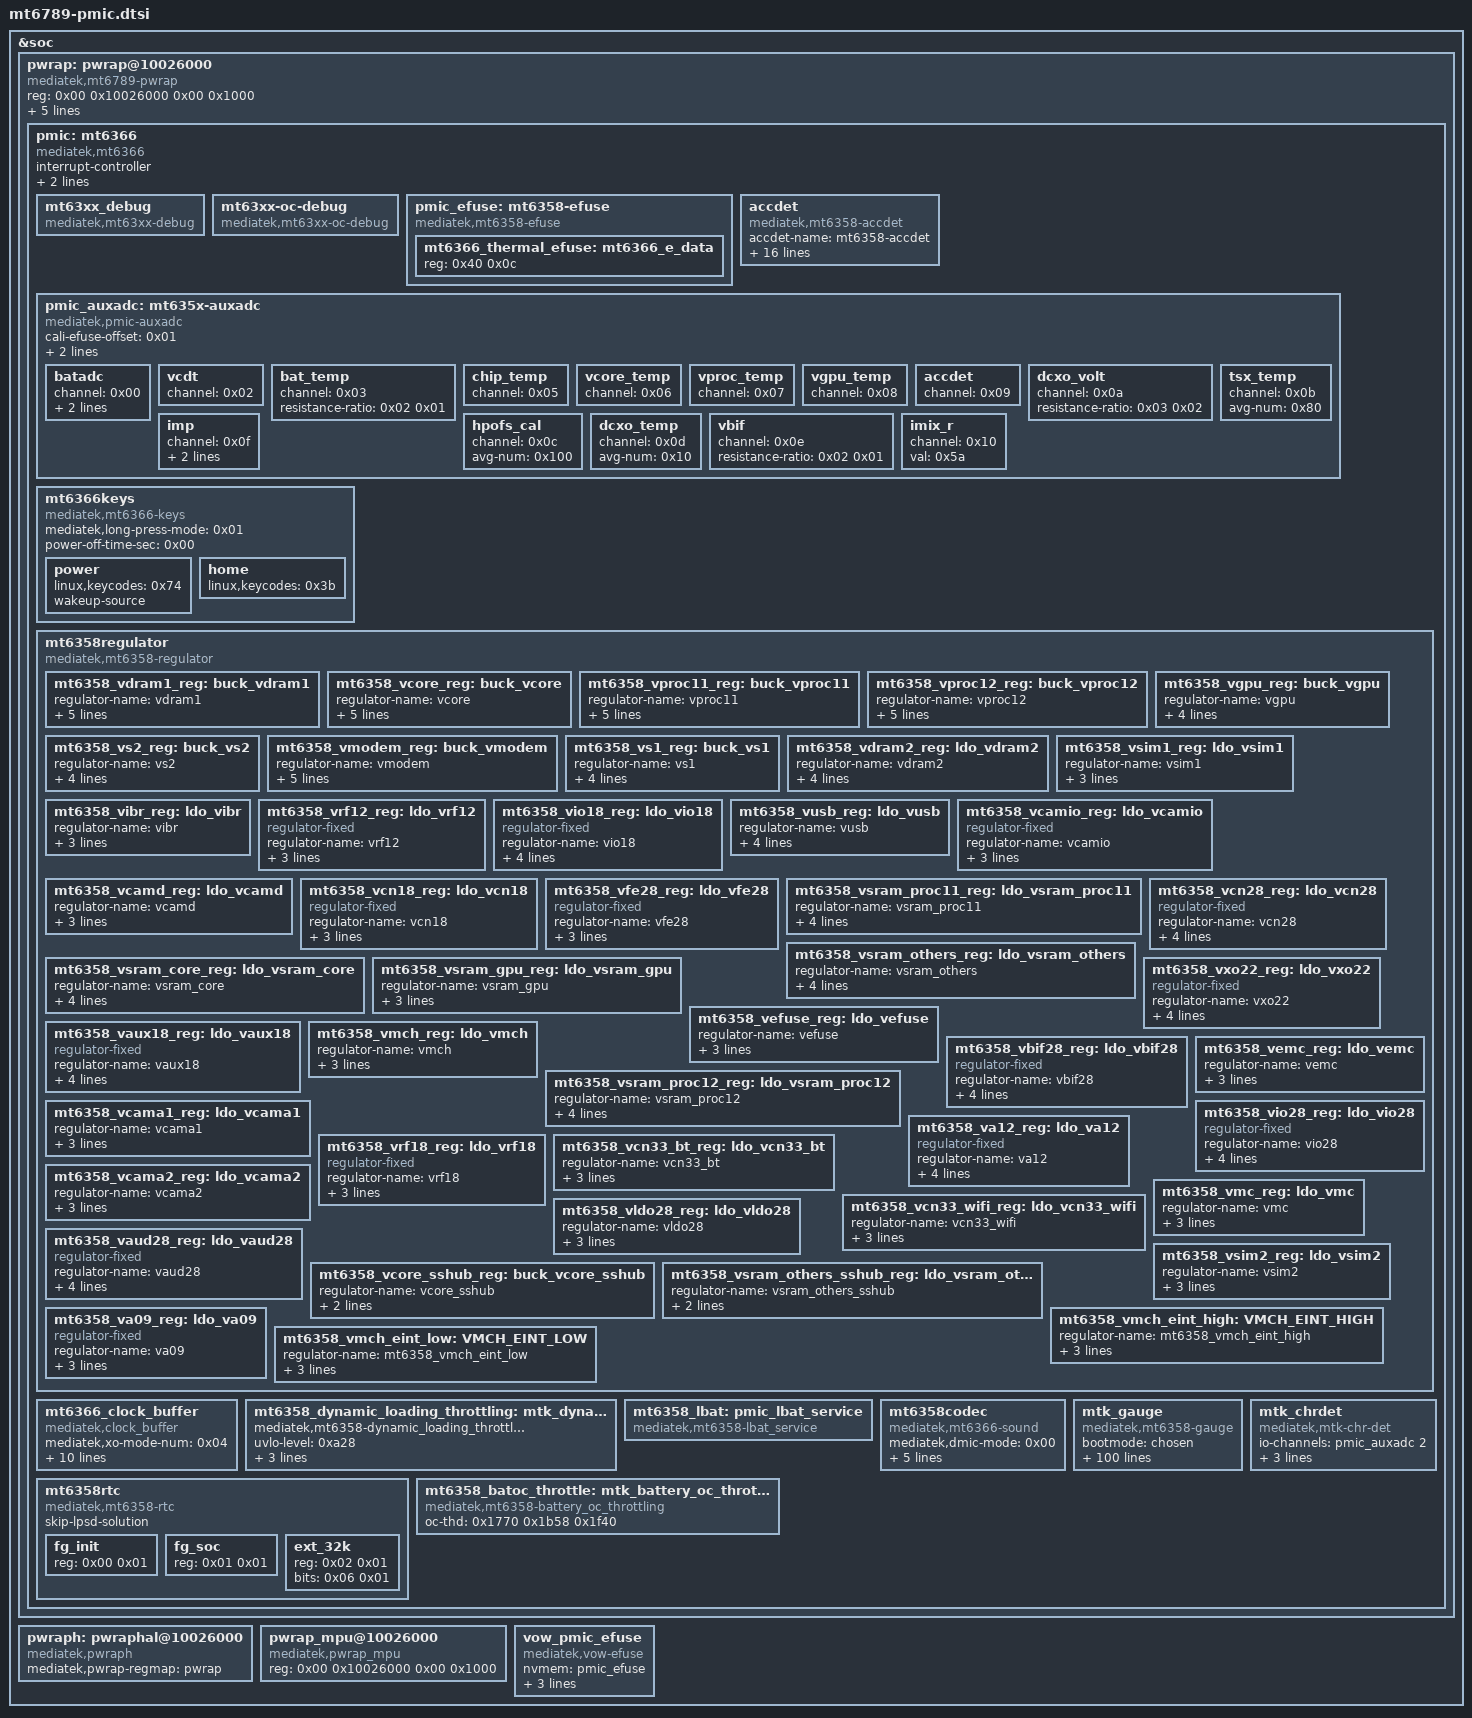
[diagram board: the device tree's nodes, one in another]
// SPDX-License-Identifier: (GPL-2.0 OR MIT)
/* MT6789 pmic blocks - split out of the soc node by tools/scripts/dts-socsplit.py */

&soc {
	pwrap: pwrap@10026000 {
		compatible = "mediatek,mt6789-pwrap";
		reg = <0x00 0x10026000 0x00 0x1000>;
		reg-names = "pwrap";
		interrupts = <GIC_SPI 252 IRQ_TYPE_LEVEL_HIGH>;
		clocks = <&infracfg_ao_clk CLK_IFRAO_PMIC_AP &infracfg_ao_clk CLK_IFRAO_PMIC_TMR &topckgen_clk CLK_TOP_PWRAP_ULPOSC_SEL &topckgen_clk CLK_TOP_OSC_D10>;
		clock-names = "spi", "wrap", "ulposc", "ulposc_osc";

		pmic: mt6366 {
			compatible = "mediatek,mt6366";
			interrupt-controller;
			#interrupt-cells = <0x02>;
			interrupt-parent = <&pio>;
			interrupts = <0x89 0x04 0x89 0x00>;

			mt63xx_debug {
				compatible = "mediatek,mt63xx-debug";
			};

			mt63xx-oc-debug {
				compatible = "mediatek,mt63xx-oc-debug";
			};

			pmic_efuse: mt6358-efuse {
				compatible = "mediatek,mt6358-efuse";
				#address-cells = <0x01>;
				#size-cells = <0x01>;

				mt6366_thermal_efuse: mt6366_e_data {
					reg = <0x40 0x0c>;
				};
			};

			accdet: accdet {
				compatible = "mediatek,mt6358-accdet";
				accdet-name = "mt6358-accdet";
				accdet-mic-vol = <0x06>;
				headset-mode-setting = <0x500 0x500 0x01 0x1f0 0x800 0x800 0x20 0x44 0x00 0x00 0x0e 0x00 0x00 0x00 0x00 0x00>;
				accdet-plugout-debounce = <0x01>;
				accdet-mic-mode = <0x01>;
				headset-eint-level-pol = <0x08>;
				headset-three-key-threshold = <0x00 0x50 0xdc 0x190>;
				headset-three-key-threshold-CDD = <0x00 0x79 0xc0 0x258>;
				headset-four-key-threshold = <0x00 0x3a 0x79 0xc0 0x190>;
				io-channels = <&pmic_auxadc 9>;
				io-channel-names = "pmic_accdet";
				nvmem = <&pmic_efuse>;
				nvmem-names = "mt63xx-accdet-efuse";
				mediatek,accdet-pmic = <0x66>;
				status = "okay";
			};

			pmic_auxadc: mt635x-auxadc {
				compatible = "mediatek,pmic-auxadc", "mediatek,mt6358-auxadc";
				#io-channel-cells = <0x01>;
				cali-efuse-offset = <0x01>;
				nvmem = <&pmic_efuse>;
				nvmem-names = "auxadc_efuse_dev";

				batadc {
					channel = <0x00>;
					resistance-ratio = <0x03 0x01>;
					avg-num = <0x80>;
				};

				vcdt {
					channel = <0x02>;
				};

				bat_temp {
					channel = <0x03>;
					resistance-ratio = <0x02 0x01>;
				};

				chip_temp {
					channel = <0x05>;
				};

				vcore_temp {
					channel = <0x06>;
				};

				vproc_temp {
					channel = <0x07>;
				};

				vgpu_temp {
					channel = <0x08>;
				};

				accdet {
					channel = <0x09>;
				};

				dcxo_volt {
					channel = <0x0a>;
					resistance-ratio = <0x03 0x02>;
				};

				tsx_temp {
					channel = <0x0b>;
					avg-num = <0x80>;
				};

				hpofs_cal {
					channel = <0x0c>;
					avg-num = <0x100>;
				};

				dcxo_temp {
					channel = <0x0d>;
					avg-num = <0x10>;
				};

				vbif {
					channel = <0x0e>;
					resistance-ratio = <0x02 0x01>;
				};

				imp {
					channel = <0x0f>;
					resistance-ratio = <0x03 0x01>;
					avg-num = <0x80>;
				};

				imix_r {
					channel = <0x10>;
					val = <0x5a>;
				};
			};

			mt6366keys: mt6366keys {
				compatible = "mediatek,mt6366-keys";
				mediatek,long-press-mode = <0x01>;
				power-off-time-sec = <0x00>;

				power {
					linux,keycodes = <0x74>;
					wakeup-source;
				};

				home {
					linux,keycodes = <0x3b>;
				};
			};

			mt6358regulator: mt6358regulator {
				compatible = "mediatek,mt6358-regulator";

				mt6358_vdram1_reg: buck_vdram1 {
					regulator-name = "vdram1";
					regulator-min-microvolt = <0x7a120>;
					regulator-max-microvolt = <0x1fda4c>;
					regulator-enable-ramp-delay = <0x00>;
					regulator-allowed-modes = <0x00 0x01>;
					regulator-always-on;
				};

				mt6358_vcore_reg: buck_vcore {
					regulator-name = "vcore";
					regulator-min-microvolt = <0x7a120>;
					regulator-max-microvolt = <0x13bdb6>;
					regulator-enable-ramp-delay = <0xc8>;
					regulator-always-on;
					regulator-allowed-modes = <0x00 0x01>;
				};

				mt6358_vproc11_reg: buck_vproc11 {
					regulator-name = "vproc11";
					regulator-min-microvolt = <0x7a120>;
					regulator-max-microvolt = <0x13bdb6>;
					regulator-enable-ramp-delay = <0xc8>;
					regulator-always-on;
					regulator-allowed-modes = <0x00 0x01>;
				};

				mt6358_vproc12_reg: buck_vproc12 {
					regulator-name = "vproc12";
					regulator-min-microvolt = <0x7a120>;
					regulator-max-microvolt = <0x13bdb6>;
					regulator-enable-ramp-delay = <0xc8>;
					regulator-always-on;
					regulator-allowed-modes = <0x00 0x01>;
				};

				mt6358_vgpu_reg: buck_vgpu {
					regulator-name = "vgpu";
					regulator-min-microvolt = <0x7a120>;
					regulator-max-microvolt = <0x13bdb6>;
					regulator-enable-ramp-delay = <0xc8>;
					regulator-allowed-modes = <0x00 0x01>;
				};

				mt6358_vs2_reg: buck_vs2 {
					regulator-name = "vs2";
					regulator-min-microvolt = <0x7a120>;
					regulator-max-microvolt = <0x1fda4c>;
					regulator-enable-ramp-delay = <0x00>;
					regulator-always-on;
				};

				mt6358_vmodem_reg: buck_vmodem {
					regulator-name = "vmodem";
					regulator-min-microvolt = <0x7a120>;
					regulator-max-microvolt = <0x13bdb6>;
					regulator-enable-ramp-delay = <0x384>;
					regulator-always-on;
					regulator-allowed-modes = <0x00 0x01>;
				};

				mt6358_vs1_reg: buck_vs1 {
					regulator-name = "vs1";
					regulator-min-microvolt = <0xf4240>;
					regulator-max-microvolt = <0x277b6c>;
					regulator-enable-ramp-delay = <0x00>;
					regulator-always-on;
				};

				mt6358_vdram2_reg: ldo_vdram2 {
					regulator-name = "vdram2";
					regulator-min-microvolt = <0x927c0>;
					regulator-max-microvolt = <0x1b7740>;
					regulator-enable-ramp-delay = <0xce4>;
					regulator-always-on;
				};

				mt6358_vsim1_reg: ldo_vsim1 {
					regulator-name = "vsim1";
					regulator-min-microvolt = <0x00>;
					regulator-max-microvolt = <0x2f4d60>;
					regulator-enable-ramp-delay = <0x21c>;
				};

				mt6358_vibr_reg: ldo_vibr {
					regulator-name = "vibr";
					regulator-min-microvolt = <0x124f80>;
					regulator-max-microvolt = <0x325aa0>;
					regulator-enable-ramp-delay = <0x3c>;
				};

				mt6358_vrf12_reg: ldo_vrf12 {
					compatible = "regulator-fixed";
					regulator-name = "vrf12";
					regulator-min-microvolt = <0x124f80>;
					regulator-max-microvolt = <0x124f80>;
					regulator-enable-ramp-delay = <0x78>;
				};

				mt6358_vio18_reg: ldo_vio18 {
					compatible = "regulator-fixed";
					regulator-name = "vio18";
					regulator-min-microvolt = <0x1b7740>;
					regulator-max-microvolt = <0x1b7740>;
					regulator-enable-ramp-delay = <0xa8c>;
					regulator-always-on;
				};

				mt6358_vusb_reg: ldo_vusb {
					regulator-name = "vusb";
					regulator-min-microvolt = <0x2dc6c0>;
					regulator-max-microvolt = <0x2f4d60>;
					regulator-enable-ramp-delay = <0x10e>;
					regulator-always-on;
				};

				mt6358_vcamio_reg: ldo_vcamio {
					compatible = "regulator-fixed";
					regulator-name = "vcamio";
					regulator-min-microvolt = <0x1b7740>;
					regulator-max-microvolt = <0x1b7740>;
					regulator-enable-ramp-delay = <0x145>;
				};

				mt6358_vcamd_reg: ldo_vcamd {
					regulator-name = "vcamd";
					regulator-min-microvolt = <0xdbba0>;
					regulator-max-microvolt = <0x1b7740>;
					regulator-enable-ramp-delay = <0x145>;
				};

				mt6358_vcn18_reg: ldo_vcn18 {
					compatible = "regulator-fixed";
					regulator-name = "vcn18";
					regulator-min-microvolt = <0x1b7740>;
					regulator-max-microvolt = <0x1b7740>;
					regulator-enable-ramp-delay = <0x10e>;
				};

				mt6358_vfe28_reg: ldo_vfe28 {
					compatible = "regulator-fixed";
					regulator-name = "vfe28";
					regulator-min-microvolt = <0x2ab980>;
					regulator-max-microvolt = <0x2ab980>;
					regulator-enable-ramp-delay = <0x10e>;
				};

				mt6358_vsram_proc11_reg: ldo_vsram_proc11 {
					regulator-name = "vsram_proc11";
					regulator-min-microvolt = <0x7a120>;
					regulator-max-microvolt = <0x13bdb6>;
					regulator-enable-ramp-delay = <0xf0>;
					regulator-always-on;
				};

				mt6358_vcn28_reg: ldo_vcn28 {
					compatible = "regulator-fixed";
					regulator-name = "vcn28";
					regulator-min-microvolt = <0x2ab980>;
					regulator-max-microvolt = <0x2ab980>;
					regulator-enable-ramp-delay = <0x10e>;
					regulator-always-on;
				};

				mt6358_vsram_others_reg: ldo_vsram_others {
					regulator-name = "vsram_others";
					regulator-min-microvolt = <0x7a120>;
					regulator-max-microvolt = <0x13bdb6>;
					regulator-enable-ramp-delay = <0xf0>;
					regulator-always-on;
				};

				mt6358_vsram_core_reg: ldo_vsram_core {
					regulator-name = "vsram_core";
					regulator-min-microvolt = <0x7a120>;
					regulator-max-microvolt = <0x13bdb6>;
					regulator-enable-ramp-delay = <0xf0>;
					regulator-always-on;
				};

				mt6358_vsram_gpu_reg: ldo_vsram_gpu {
					regulator-name = "vsram_gpu";
					regulator-min-microvolt = <0x7a120>;
					regulator-max-microvolt = <0x13bdb6>;
					regulator-enable-ramp-delay = <0xf0>;
				};

				mt6358_vxo22_reg: ldo_vxo22 {
					compatible = "regulator-fixed";
					regulator-name = "vxo22";
					regulator-min-microvolt = <0x2191c0>;
					regulator-max-microvolt = <0x2191c0>;
					regulator-enable-ramp-delay = <0x78>;
					regulator-always-on;
				};

				mt6358_vefuse_reg: ldo_vefuse {
					regulator-name = "vefuse";
					regulator-min-microvolt = <0x19f0a0>;
					regulator-max-microvolt = <0x1cfde0>;
					regulator-enable-ramp-delay = <0x10e>;
				};

				mt6358_vaux18_reg: ldo_vaux18 {
					compatible = "regulator-fixed";
					regulator-name = "vaux18";
					regulator-min-microvolt = <0x1b7740>;
					regulator-max-microvolt = <0x1b7740>;
					regulator-enable-ramp-delay = <0x10e>;
					regulator-always-on;
				};

				mt6358_vmch_reg: ldo_vmch {
					regulator-name = "vmch";
					regulator-min-microvolt = <0x2c4020>;
					regulator-max-microvolt = <0x325aa0>;
					regulator-enable-ramp-delay = <0x3c>;
				};

				mt6358_vbif28_reg: ldo_vbif28 {
					compatible = "regulator-fixed";
					regulator-name = "vbif28";
					regulator-min-microvolt = <0x2ab980>;
					regulator-max-microvolt = <0x2ab980>;
					regulator-enable-ramp-delay = <0x10e>;
					regulator-always-on;
				};

				mt6358_vsram_proc12_reg: ldo_vsram_proc12 {
					regulator-name = "vsram_proc12";
					regulator-min-microvolt = <0x7a120>;
					regulator-max-microvolt = <0x13bdb6>;
					regulator-enable-ramp-delay = <0xf0>;
					regulator-always-on;
				};

				mt6358_vcama1_reg: ldo_vcama1 {
					regulator-name = "vcama1";
					regulator-min-microvolt = <0x1b7740>;
					regulator-max-microvolt = <0x2dc6c0>;
					regulator-enable-ramp-delay = <0x145>;
				};

				mt6358_vemc_reg: ldo_vemc {
					regulator-name = "vemc";
					regulator-min-microvolt = <0x2c4020>;
					regulator-max-microvolt = <0x325aa0>;
					regulator-enable-ramp-delay = <0x3c>;
				};

				mt6358_vio28_reg: ldo_vio28 {
					compatible = "regulator-fixed";
					regulator-name = "vio28";
					regulator-min-microvolt = <0x2ab980>;
					regulator-max-microvolt = <0x2ab980>;
					regulator-enable-ramp-delay = <0x10e>;
					regulator-always-on;
				};

				mt6358_va12_reg: ldo_va12 {
					compatible = "regulator-fixed";
					regulator-name = "va12";
					regulator-min-microvolt = <0x124f80>;
					regulator-max-microvolt = <0x124f80>;
					regulator-enable-ramp-delay = <0x10e>;
					regulator-always-on;
				};

				mt6358_vrf18_reg: ldo_vrf18 {
					compatible = "regulator-fixed";
					regulator-name = "vrf18";
					regulator-min-microvolt = <0x1b7740>;
					regulator-max-microvolt = <0x1b7740>;
					regulator-enable-ramp-delay = <0x78>;
				};

				mt6358_vcn33_bt_reg: ldo_vcn33_bt {
					regulator-name = "vcn33_bt";
					regulator-min-microvolt = <0x325aa0>;
					regulator-max-microvolt = <0x3567e0>;
					regulator-enable-ramp-delay = <0x10e>;
				};

				mt6358_vcn33_wifi_reg: ldo_vcn33_wifi {
					regulator-name = "vcn33_wifi";
					regulator-min-microvolt = <0x325aa0>;
					regulator-max-microvolt = <0x3567e0>;
					regulator-enable-ramp-delay = <0x10e>;
				};

				mt6358_vcama2_reg: ldo_vcama2 {
					regulator-name = "vcama2";
					regulator-min-microvolt = <0x1b7740>;
					regulator-max-microvolt = <0x2dc6c0>;
					regulator-enable-ramp-delay = <0x145>;
				};

				mt6358_vmc_reg: ldo_vmc {
					regulator-name = "vmc";
					regulator-min-microvolt = <0x1b7740>;
					regulator-max-microvolt = <0x325aa0>;
					regulator-enable-ramp-delay = <0x3c>;
				};

				mt6358_vldo28_reg: ldo_vldo28 {
					regulator-name = "vldo28";
					regulator-min-microvolt = <0x2ab980>;
					regulator-max-microvolt = <0x2dc6c0>;
					regulator-enable-ramp-delay = <0x10e>;
				};

				mt6358_vaud28_reg: ldo_vaud28 {
					compatible = "regulator-fixed";
					regulator-name = "vaud28";
					regulator-min-microvolt = <0x2ab980>;
					regulator-max-microvolt = <0x2ab980>;
					regulator-enable-ramp-delay = <0x10e>;
					regulator-always-on;
				};

				mt6358_vsim2_reg: ldo_vsim2 {
					regulator-name = "vsim2";
					regulator-min-microvolt = <0x00>;
					regulator-max-microvolt = <0x2f4d60>;
					regulator-enable-ramp-delay = <0x21c>;
				};

				mt6358_vcore_sshub_reg: buck_vcore_sshub {
					regulator-name = "vcore_sshub";
					regulator-min-microvolt = <0x7a120>;
					regulator-max-microvolt = <0x13bdb6>;
				};

				mt6358_vsram_others_sshub_reg: ldo_vsram_others_sshub {
					regulator-name = "vsram_others_sshub";
					regulator-min-microvolt = <0x7a120>;
					regulator-max-microvolt = <0x13bdb6>;
				};

				mt6358_va09_reg: ldo_va09 {
					regulator-name = "va09";
					compatible = "regulator-fixed";
					regulator-min-microvolt = <0xdbba0>;
					regulator-max-microvolt = <0xdbba0>;
					regulator-enable-ramp-delay = <0x108>;
				};

				mt6358_vmch_eint_high: VMCH_EINT_HIGH {
					regulator-name = "mt6358_vmch_eint_high";
					regulator-min-microvolt = <0x2c4020>;
					regulator-max-microvolt = <0x325aa0>;
					regulator-enable-ramp-delay = <0x3c>;
				};

				mt6358_vmch_eint_low: VMCH_EINT_LOW {
					regulator-name = "mt6358_vmch_eint_low";
					regulator-min-microvolt = <0x2c4020>;
					regulator-max-microvolt = <0x325aa0>;
					regulator-enable-ramp-delay = <0x3c>;
				};
			};

			mt6366_clock_buffer: mt6366_clock_buffer {
				compatible = "mediatek,clock_buffer";
				mediatek,xo-mode-num = <0x04>;
				mediatek,xo-buf-support = <0x01 0x01 0x01 0x01 0x00 0x00 0x01>;
				mediatek,xo-buf-allow-control = <0x00 0x01 0x01 0x01 0x00 0x00 0x01>;
				mediatek,xo-buf-name = "XO_SOC", "XO_WCN", "XO_NFC", "XO_CEL", "RSV1", "RSV2", "XO_EXT";
				mediatek,dcxo-drv-curr-support;
				mediatek,clkbuf-pmic-central-base;
				mediatek,enable;
				clkbuf_ctl = <&clock_buffer_ctrl>;
			};

			mt6358_dynamic_loading_throttling: mtk_dynamic_loading_throttling {
				compatible = "mediatek,mt6358-dynamic_loading_throttling";
				uvlo-level = <0xa28>;
				io-channels = <&pmic_auxadc 15 &pmic_auxadc 16 &pmic_auxadc 0>;
				io-channel-names = "pmic_ptim", "pmic_imix_r", "pmic_batadc";
				bootmode = <&chosen>;
			};

			mt6358_lbat: pmic_lbat_service {
				compatible = "mediatek,mt6358-lbat_service";
			};

			mt6358codec: mt6358codec {
				compatible = "mediatek,mt6366-sound";
				mediatek,dmic-mode = <0x00>;
				mediatek,mic-type = <0x01>;
				io-channels = <&pmic_auxadc 12>;
				io-channel-names = "pmic_hpofs_cal";
				nvmem = <&pmic_efuse>;
				nvmem-names = "pmic-hp-efuse";
				reg_vaud28-supply = <&mt6358_vaud28_reg>;
			};

			mt6358rtc: mt6358rtc {
				compatible = "mediatek,mt6358-rtc";
				skip-lpsd-solution;
				#address-cells = <0x01>;
				#size-cells = <0x01>;

				fg_init: fg_init {
					reg = <0x00 0x01>;
				};

				fg_soc: fg_soc {
					reg = <0x01 0x01>;
				};

				ext_32k: ext_32k {
					reg = <0x02 0x01>;
					bits = <0x06 0x01>;
				};
			};

			mtk_gauge: mtk_gauge {
				compatible = "mediatek,mt6358-gauge";
				bootmode = <&chosen>;
				io-channels = <&pmic_auxadc 0x03 &pmic_auxadc 0x00 &pmic_auxadc 0x0e &pmic_auxadc 0x0f &auxadc 0x04 &pmic_auxadc 0x10>;
				io-channel-names = "pmic_battery_temp", "pmic_battery_voltage", "pmic_bif_voltage", "pmic_ptim_voltage", "batteryID-channel", "pmic_ptim_r";
				nvmem-cells = <&fg_init &fg_soc>;
				nvmem-cell-names = "initialization", "state-of-charge";
				charger = <&mt6375_chg>;
				DIFFERENCE_FULLOCV_ITH = <0xc8>;
				SHUTDOWN_1_TIME = <0x1e>;
				KEEP_100_PERCENT = <0x01>;
				R_FG_VALUE = <0x05>;
				EMBEDDED_SEL = <0x01>;
				PMIC_SHUTDOWN_CURRENT = <0x14>;
				FG_METER_RESISTANCE = <0x64>;
				CAR_TUNE_VALUE = <0x64>;
				PMIC_MIN_VOL = <0x82dc>;
				POWERON_SYSTEM_IBOOT = <0x1f4>;
				SHUTDOWN_GAUGE0_VOLTAGE = <0x84d0>;
				TEMPERATURE_T0 = <0x32>;
				TEMPERATURE_T1 = <0x19>;
				TEMPERATURE_T2 = <0x0a>;
				TEMPERATURE_T3 = <0x00>;
				TEMPERATURE_T4 = <0xfffffff6>;
				g_FG_PSEUDO100_T0 = <0x64>;
				g_FG_PSEUDO100_T1 = <0x64>;
				g_FG_PSEUDO100_T2 = <0x64>;
				g_FG_PSEUDO100_T3 = <0x64>;
				g_FG_PSEUDO100_T4 = <0x64>;
				Q_MAX_SYS_VOLTAGE_BAT0 = <0xd16>;
				Q_MAX_SYS_VOLTAGE_BAT1 = <0xd16>;
				Q_MAX_SYS_VOLTAGE_BAT2 = <0xd16>;
				Q_MAX_SYS_VOLTAGE_BAT3 = <0xd16>;
				COM_FG_METER_RESISTANCE = <0x64>;
				COM_R_FG_VALUE = <0x00>;
				enable_tmp_intr_suspend = <0x00>;
				ACTIVE_TABLE = <0x05>;
				MULTI_TEMP_GAUGE0 = <0x01>;
				RBAT_PULL_UP_VOLT = <0xaf0>;
				tran_Q_diff = <0x1388 0x1388 0x1388 0x1388>;
				battery0_profile_t0_num = <0x64>;
				battery0_profile_t0_col = <0x04>;
				battery0_profile_t0 = <0x00 0xacd9 0x30c 0x2ec 0x1fa 0xac3f 0x30c 0x2ec 0x3f4 0xabbf 0x314 0x2f3 0x5ee 0xab45 0x30c 0x2ec 0x7e8 0xaad7 0x30c 0x2ec 0x9e2 0xaa66 0x30c 0x2ec 0xbdc 0xa9f8 0x30d 0x2ed 0xdd6 0xa98a 0x314 0x2f3 0xfd0 0xa919 0x314 0x2f3 0x11cb 0xa8a8 0x315 0x2f4 0x13c5 0xa833 0x31d 0x2fd 0x15bf 0xa7b9 0x314 0x2f3 0x17b9 0xa741 0x315 0x2f4 0x19b3 0xa6c7 0x31e 0x2fd 0x1bad 0xa64c 0x31e 0x2fd 0x1da7 0xa5ce 0x31e 0x2fd 0x1fa1 0xa552 0x31e 0x2fd 0x219b 0xa4d9 0x31e 0x2fd 0x2395 0xa45d 0x31e 0x2fd 0x258f 0xa3e4 0x322 0x301 0x2789 0xa36f 0x330 0x30d 0x2983 0xa2f6 0x330 0x30d 0x2b7d 0xa280 0x32d 0x30b 0x2d77 0xa206 0x326 0x305 0x2f71 0xa191 0x329 0x306 0x316c 0xa11f 0x332 0x30f 0x3366 0xa0ad 0x338 0x316 0x3560 0xa03f 0x33b 0x318 0x375a 0x9fcd 0x341 0x31e 0x3954 0x9f5e 0x341 0x31e 0x3b4e 0x9ef3 0x341 0x31e 0x3d48 0x9e88 0x341 0x31e 0x3f42 0x9e23 0x345 0x321 0x413c 0x9dbd 0x34d 0x32b 0x4336 0x9d5a 0x357 0x332 0x4530 0x9cfa 0x35f 0x33c 0x472a 0x9c9c 0x369 0x343 0x4924 0x9c3d 0x371 0x34d 0x4b1e 0x9be1 0x37b 0x355 0x4d18 0x9b88 0x387 0x361 0x4f12 0x9b31 0x395 0x370 0x510c 0x9ad7 0x3a7 0x380 0x5307 0x9a7a 0x3bd 0x394 0x5501 0x9a0b 0x3b8 0x390 0x56fb 0x9978 0x37d 0x356 0x58f5 0x98e3 0x33b 0x318 0x5aef 0x9872 0x321 0x300 0x5ce9 0x981b 0x31e 0x2fd 0x5ee3 0x97cf 0x31e 0x2fd 0x60dd 0x9788 0x319 0x2f7 0x62d7 0x9745 0x314 0x2f3 0x64d1 0x9708 0x31a 0x2f8 0x66cb 0x96cf 0x319 0x2f7 0x68c5 0x9695 0x31a 0x2f8 0x6abf 0x965c 0x318 0x2f6 0x6cb9 0x9628 0x31b 0x2fa 0x6eb3 0x95f8 0x324 0x302 0x70ad 0x95c7 0x320 0x2ff 0x72a8 0x9599 0x324 0x302 0x74a2 0x956d 0x326 0x305 0x769c 0x9541 0x32d 0x30b 0x7896 0x9518 0x330 0x30d 0x7a90 0x94ee 0x330 0x30d 0x7c8a 0x94ca 0x33c 0x31a 0x7e84 0x94a5 0x33a 0x318 0x807e 0x9485 0x347 0x324 0x8278 0x9463 0x351 0x32d 0x8472 0x9443 0x35a 0x336 0x866c 0x9424 0x362 0x33f 0x8866 0x9404 0x364 0x341 0x8a60 0x93dd 0x364 0x341 0x8c5a 0x9397 0x33f 0x31c 0x8e54 0x9344 0x31a 0x2f7 0x904e 0x92f9 0x314 0x2f3 0x9248 0x92c8 0x325 0x304 0x9443 0x9298 0x31f 0x2fd 0x963d 0x926f 0x325 0x305 0x9837 0x923d 0x31f 0x2fd 0x9a31 0x920f 0x325 0x305 0x9c2b 0x91e9 0x326 0x305 0x9e25 0x91c2 0x326 0x305 0xa01f 0x919d 0x338 0x316 0xa219 0x9168 0x330 0x30d 0xa413 0x9126 0x326 0x305 0xa60d 0x90e4 0x31e 0x2fd 0xa807 0x90a8 0x330 0x30d 0xaa01 0x9062 0x32f 0x30c 0xabfb 0x900c 0x314 0x2f3 0xadf5 0x8fdd 0x304 0x2e3 0xafef 0x8fce 0x30e 0x2ee 0xb1e9 0x8fc7 0x32b 0x307 0xb3e4 0x8fba 0x34c 0x32b 0xb5de 0x8fa9 0x36b 0x346 0xb7d8 0x8f84 0x39a 0x374 0xb9d2 0x8f04 0x390 0x368 0xba3c 0x8da9 0x34c 0x32b 0xbaa6 0x8ba7 0x362 0x33f 0xbb10 0x88ee 0x391 0x36a 0xbb7a 0x8503 0x3e0 0x3b7 0xbbe4 0x8061 0x477 0x447>;
				battery0_profile_t1_num = <0x64>;
				battery0_profile_t1_col = <0x04>;
				battery0_profile_t1 = <0x00 0xad5b 0x30c 0x2ec 0x1fa 0xaca6 0x30c 0x2ec 0x3f4 0xac1d 0x314 0x2f3 0x5ee 0xaba3 0x30c 0x2ec 0x7e8 0xab32 0x30c 0x2ec 0x9e2 0xaac5 0x30c 0x2ec 0xbdc 0xaa5a 0x30d 0x2ed 0xdd6 0xa9f0 0x314 0x2f3 0xfd0 0xa984 0x314 0x2f3 0x11cb 0xa914 0x315 0x2f4 0x13c5 0xa89f 0x31d 0x2fd 0x15bf 0xa825 0x314 0x2f3 0x17b9 0xa7b0 0x315 0x2f4 0x19b3 0xa737 0x31e 0x2fd 0x1bad 0xa6bc 0x31e 0x2fd 0x1da7 0xa640 0x31e 0x2fd 0x1fa1 0xa5c8 0x31e 0x2fd 0x219b 0xa54b 0x31e 0x2fd 0x2395 0xa4cf 0x31e 0x2fd 0x258f 0xa457 0x322 0x301 0x2789 0xa3dd 0x330 0x30d 0x2983 0xa362 0x330 0x30d 0x2b7d 0xa2ea 0x32d 0x30b 0x2d77 0xa276 0x326 0x305 0x2f71 0xa1ff 0x329 0x306 0x316c 0xa18c 0x332 0x30f 0x3366 0xa11a 0x338 0x316 0x3560 0xa0a7 0x33b 0x318 0x375a 0xa037 0x341 0x31e 0x3954 0x9fc8 0x341 0x31e 0x3b4e 0x9f5d 0x341 0x31e 0x3d48 0x9ef4 0x341 0x31e 0x3f42 0x9e8b 0x345 0x321 0x413c 0x9e22 0x34d 0x32b 0x4336 0x9dbd 0x357 0x332 0x4530 0x9d5c 0x35f 0x33c 0x472a 0x9cfb 0x369 0x343 0x4924 0x9c9c 0x371 0x34d 0x4b1e 0x9c3c 0x37b 0x355 0x4d18 0x9be1 0x387 0x361 0x4f12 0x9b8a 0x395 0x370 0x510c 0x9b32 0x3a7 0x380 0x5307 0x9ad6 0x3bd 0x394 0x5501 0x9a74 0x3b8 0x390 0x56fb 0x9a05 0x37d 0x356 0x58f5 0x9982 0x33b 0x318 0x5aef 0x98f9 0x321 0x300 0x5ce9 0x9880 0x31e 0x2fd 0x5ee3 0x981b 0x31e 0x2fd 0x60dd 0x97c6 0x319 0x2f7 0x62d7 0x977d 0x314 0x2f3 0x64d1 0x973a 0x31a 0x2f8 0x66cb 0x96fb 0x319 0x2f7 0x68c5 0x96c0 0x31a 0x2f8 0x6abf 0x9689 0x318 0x2f6 0x6cb9 0x9652 0x31b 0x2fa 0x6eb3 0x961f 0x324 0x302 0x70ad 0x95f0 0x320 0x2ff 0x72a8 0x95c3 0x324 0x302 0x74a2 0x9591 0x326 0x305 0x769c 0x9564 0x32d 0x30b 0x7896 0x953d 0x330 0x30d 0x7a90 0x9518 0x330 0x30d 0x7c8a 0x94f0 0x33c 0x31a 0x7e84 0x94cd 0x33a 0x318 0x807e 0x94ac 0x347 0x324 0x8278 0x948d 0x351 0x32d 0x8472 0x946f 0x35a 0x336 0x866c 0x9450 0x362 0x33f 0x8866 0x9432 0x364 0x341 0x8a60 0x9417 0x364 0x341 0x8c5a 0x93fd 0x33f 0x31c 0x8e54 0x93d8 0x31a 0x2f7 0x904e 0x93b6 0x314 0x2f3 0x9248 0x9390 0x325 0x304 0x9443 0x9365 0x31f 0x2fd 0x963d 0x933f 0x325 0x305 0x9837 0x9311 0x31f 0x2fd 0x9a31 0x92e7 0x325 0x305 0x9c2b 0x92bc 0x326 0x305 0x9e25 0x9295 0x326 0x305 0xa01f 0x9272 0x338 0x316 0xa219 0x9250 0x330 0x30d 0xa413 0x9225 0x326 0x305 0xa60d 0x91f2 0x31e 0x2fd 0xa807 0x91ac 0x330 0x30d 0xaa01 0x916c 0x32f 0x30c 0xabfb 0x9134 0x314 0x2f3 0xadf5 0x90ed 0x304 0x2e3 0xafef 0x9094 0x30e 0x2ee 0xb1e9 0x9064 0x32b 0x307 0xb3e4 0x9055 0x34c 0x32b 0xb5de 0x9045 0x36b 0x346 0xb7d8 0x9039 0x39a 0x374 0xb9d2 0x9029 0x390 0x368 0xba3c 0x900a 0x34c 0x32b 0xbaa6 0x8db5 0x362 0x33f 0xbb10 0x8a76 0x391 0x36a 0xbb7a 0x8677 0x3e0 0x3b7 0xbbe4 0x84f1 0x477 0x447>;
				battery0_profile_t2_num = <0x64>;
				battery0_profile_t2_col = <0x04>;
				battery0_profile_t2 = <0x00 0xacbd 0x757 0x7d1 0x1fa 0xac1b 0x757 0x7d1 0x3f4 0xaba4 0x757 0x7d1 0x5ee 0xab33 0x745 0x7bf 0x7e8 0xaacc 0x73c 0x7b5 0x9e2 0xaa61 0x72c 0x7a3 0xbdc 0xa9fc 0x732 0x7a9 0xdd6 0xa98c 0x718 0x78e 0xfd0 0xa91e 0x70e 0x783 0x11cb 0xa8aa 0x6fd 0x771 0x13c5 0xa839 0x6f4 0x767 0x15bf 0xa7bf 0x6e4 0x756 0x17b9 0xa747 0x6e2 0x754 0x19b3 0xa6cd 0x6d2 0x743 0x1bad 0xa64f 0x6cf 0x740 0x1da7 0xa5d3 0x6c0 0x730 0x1fa1 0xa558 0x6c0 0x730 0x219b 0xa4de 0x6c0 0x730 0x2395 0xa464 0x6be 0x72f 0x258f 0xa3eb 0x6b7 0x727 0x2789 0xa374 0x6b9 0x729 0x2983 0xa2fc 0x6bd 0x72d 0x2b7d 0xa284 0x6b1 0x71f 0x2d77 0xa212 0x6bc 0x72c 0x2f71 0xa19d 0x6c8 0x739 0x316c 0xa12b 0x6bd 0x72e 0x3366 0xa0b8 0x6bc 0x72c 0x3560 0xa049 0x6c7 0x738 0x375a 0x9fd8 0x6c6 0x737 0x3954 0x9f6d 0x6d4 0x747 0x3b4e 0x9f03 0x6e0 0x753 0x3d48 0x9e9a 0x6f0 0x762 0x3f42 0x9e2d 0x6fb 0x770 0x413c 0x9dc3 0x70d 0x782 0x4336 0x9d59 0x719 0x790 0x4530 0x9cf3 0x71c 0x793 0x472a 0x9c90 0x729 0x79f 0x4924 0x9c30 0x733 0x7ab 0x4b1e 0x9bd1 0x733 0x7ab 0x4d18 0x9b6e 0x730 0x7a7 0x4f12 0x9b06 0x71f 0x795 0x510c 0x9a99 0x708 0x77d 0x5307 0x9a27 0x6e3 0x755 0x5501 0x99af 0x6a8 0x717 0x56fb 0x9936 0x66e 0x6d8 0x58f5 0x98c5 0x638 0x69f 0x5aef 0x985f 0x610 0x674 0x5ce9 0x9802 0x5f0 0x653 0x5ee3 0x97af 0x5da 0x63b 0x60dd 0x9764 0x5d1 0x631 0x62d7 0x971f 0x5cc 0x62d 0x64d1 0x96df 0x5c8 0x628 0x66cb 0x96a2 0x5c8 0x628 0x68c5 0x966a 0x5c8 0x628 0x6abf 0x9633 0x5c3 0x622 0x6cb9 0x9601 0x5ce 0x62f 0x6eb3 0x95ce 0x5cf 0x630 0x70ad 0x959e 0x5d3 0x633 0x72a8 0x9572 0x5d5 0x634 0x74a2 0x9548 0x5d7 0x637 0x769c 0x951d 0x5df 0x641 0x7896 0x94f3 0x5e8 0x64a 0x7a90 0x94ce 0x5ec 0x64f 0x7c8a 0x94aa 0x5ec 0x64f 0x7e84 0x9488 0x5ec 0x64f 0x807e 0x9469 0x5f2 0x654 0x8278 0x944c 0x5fb 0x65f 0x8472 0x942d 0x5fe 0x661 0x866c 0x9412 0x5fe 0x661 0x8866 0x93f8 0x5fe 0x661 0x8a60 0x93de 0x5fe 0x661 0x8c5a 0x93c4 0x5f7 0x659 0x8e54 0x93ab 0x5f4 0x657 0x904e 0x9394 0x5fc 0x65f 0x9248 0x937f 0x604 0x668 0x9443 0x9366 0x615 0x679 0x963d 0x9346 0x609 0x66e 0x9837 0x931e 0x5ff 0x663 0x9a31 0x92f0 0x5f6 0x658 0x9c2b 0x92c4 0x5fc 0x65f 0x9e25 0x929a 0x614 0x678 0xa01f 0x9272 0x627 0x68d 0xa219 0x9241 0x641 0x6a9 0xa413 0x9204 0x65b 0x6c4 0xa60d 0x91c5 0x67f 0x6ea 0xa807 0x9184 0x682 0x6ef 0xaa01 0x9147 0x6a2 0x712 0xabfb 0x90f9 0x6c7 0x738 0xadf5 0x909c 0x6da 0x74c 0xafef 0x9069 0x6f4 0x767 0xb1e9 0x904e 0x71f 0x795 0xb3e4 0x9039 0x75d 0x7d9 0xb5de 0x9020 0x7b6 0x836 0xb7d8 0x9006 0x844 0x8cc 0xb9d2 0x8fd1 0x8e4 0x977 0xba3c 0x8f5e 0x9de 0xa82 0xbaa6 0x8e0a 0xadc 0xb91 0xbb10 0x8be4 0xd05 0xddd 0xbb7a 0x8706 0x1208 0x1335 0xbbe4 0x84f5 0x1e78 0x2072>;
				battery0_profile_t3_num = <0x64>;
				battery0_profile_t3_col = <0x04>;
				battery0_profile_t3 = <0x00 0xad5e 0xab3 0xb65 0x1fa 0xac86 0xab3 0xb65 0x3f4 0xabf0 0xac5 0xb78 0x5ee 0xab76 0xab2 0xb65 0x7e8 0xab06 0xaa0 0xb51 0x9e2 0xaa9a 0xa90 0xb41 0xbdc 0xaa2e 0xa98 0xb47 0xdd6 0xa9c5 0xa85 0xb33 0xfd0 0xa955 0xa6b 0xb18 0x11cb 0xa8e7 0xa6a 0xb17 0x13c5 0xa875 0xa57 0xb02 0x15bf 0xa7fc 0xa3e 0xae9 0x17b9 0xa786 0xa36 0xadf 0x19b3 0xa70a 0xa2d 0xad6 0x1bad 0xa690 0xa25 0xacd 0x1da7 0xa618 0xa23 0xacb 0x1fa1 0xa59e 0xa0f 0xab7 0x219b 0xa522 0x9fb 0xaa0 0x2395 0xa4aa 0x9fe 0xaa4 0x258f 0xa42e 0x9f1 0xa97 0x2789 0xa3b6 0x9f5 0xa9b 0x2983 0xa33d 0x9e9 0xa8e 0x2b7d 0xa2c8 0x9f0 0xa95 0x2d77 0xa251 0x9ee 0xa93 0x2f71 0xa1dc 0x9ea 0xa8e 0x316c 0xa168 0x9f0 0xa95 0x3366 0xa0f5 0x9f2 0xa97 0x3560 0xa084 0x9f9 0xa9e 0x375a 0xa014 0x9f9 0xa9e 0x3954 0x9fa6 0xa01 0xaa7 0x3b4e 0x9f39 0xa1c 0xac4 0x3d48 0x9ecd 0xa34 0xade 0x3f42 0x9e5c 0xa42 0xaed 0x413c 0x9deb 0xa44 0xaef 0x4336 0x9d7c 0xa3f 0xae9 0x4530 0x9d0e 0xa39 0xae3 0x472a 0x9ca0 0xa27 0xacf 0x4924 0x9c35 0xa1c 0xac4 0x4b1e 0x9bcb 0xa0b 0xab2 0x4d18 0x9b5e 0x9e5 0xa89 0x4f12 0x9aef 0x9c6 0xa69 0x510c 0x9a7e 0x9a2 0xa42 0x5307 0x9a0c 0x97a 0xa17 0x5501 0x9999 0x94a 0x9e4 0x56fb 0x992b 0x91c 0x9b3 0x58f5 0x98c4 0x8fd 0x992 0x5aef 0x9864 0x8e6 0x97a 0x5ce9 0x980b 0x8d4 0x967 0x5ee3 0x97b8 0x8c6 0x958 0x60dd 0x976d 0x8be 0x94f 0x62d7 0x9725 0x8b5 0x946 0x64d1 0x96e0 0x8bb 0x94d 0x66cb 0x96a0 0x8be 0x94f 0x68c5 0x9665 0x8c3 0x955 0x6abf 0x962c 0x8cc 0x95e 0x6cb9 0x95f6 0x8d6 0x969 0x6eb3 0x95c1 0x8dd 0x971 0x70ad 0x9591 0x8e8 0x97b 0x72a8 0x9563 0x8f4 0x989 0x74a2 0x9536 0x902 0x998 0x769c 0x950c 0x90f 0x9a6 0x7896 0x94e1 0x912 0x9a9 0x7a90 0x94ba 0x91e 0x9b4 0x7c8a 0x9494 0x92a 0x9c2 0x7e84 0x9472 0x938 0x9d1 0x807e 0x9451 0x945 0x9df 0x8278 0x9431 0x948 0x9e1 0x8472 0x9413 0x94d 0x9e8 0x866c 0x93f8 0x950 0x9ea 0x8866 0x93e2 0x964 0x9ff 0x8a60 0x93cf 0x97f 0xa1c 0x8c5a 0x93bd 0x999 0xa39 0x8e54 0x93aa 0x9c8 0xa6a 0x904e 0x9394 0x9f0 0xa95 0x9248 0x937f 0xa28 0xad1 0x9443 0x9366 0xa60 0xb0d 0x963d 0x934b 0xa9d 0xb4c 0x9837 0x932a 0xaea 0xb9f 0x9a31 0x9303 0xb33 0xbed 0x9c2b 0x92dc 0xb8a 0xc4a 0x9e25 0x92b1 0xbeb 0xcb0 0xa01f 0x9280 0xc4d 0xd19 0xa219 0x924c 0xcaf 0xd82 0xa413 0x920c 0xd19 0xdf2 0xa60d 0x91c9 0xd8d 0xe6e 0xa807 0x9185 0xe11 0xefa 0xaa01 0x9140 0xea0 0xf93 0xabfb 0x90ed 0xf38 0x1035 0xadf5 0x9096 0xfe0 0x10e8 0xafef 0x9051 0x109b 0x11af 0xb1e9 0x901f 0x1192 0x12b6 0xb3e4 0x8ffe 0x12c9 0x1400 0xb5de 0x8fdc 0x143f 0x158f 0xb7d8 0x8fb3 0x1643 0x17b5 0xb9d2 0x8f74 0x18ea 0x1a88 0xba3c 0x8f03 0x1cac 0x1e89 0xbaa6 0x8df8 0x2259 0x2494 0xbb10 0x8c14 0x2cc9 0x2fb1 0xbb7a 0x899b 0x40fc 0x4534 0xbbe4 0x899b 0x40fc 0x4534>;
				battery0_profile_t4_num = <0x64>;
				battery0_profile_t4_col = <0x04>;
				battery0_profile_t4 = <0x00 0xacbd 0x17d2 0x195d 0x1fa 0xabc3 0x17d3 0x195f 0x3f4 0xab21 0x180e 0x199e 0x5ee 0xaa8b 0x17b5 0x193f 0x7e8 0xaa01 0x1782 0x1909 0x9e2 0xa978 0x177e 0x1904 0xbdc 0xa8fb 0x1731 0x18b2 0xdd6 0xa88a 0x1718 0x1897 0xfd0 0xa818 0x170e 0x188d 0x11cb 0xa790 0x16a2 0x181a 0x13c5 0xa71e 0x1684 0x17fc 0x15bf 0xa6a3 0x1652 0x17c5 0x17b9 0xa631 0x1634 0x17a5 0x19b3 0xa5bf 0x15fd 0x1769 0x1bad 0xa541 0x15bf 0x1729 0x1da7 0xa4c6 0x1592 0x16f8 0x1fa1 0xa456 0x158d 0x16f3 0x219b 0xa3e3 0x156a 0x16ce 0x2395 0xa368 0x1523 0x1682 0x258f 0xa2f8 0x1506 0x1664 0x2789 0xa286 0x14e4 0x1640 0x2983 0xa215 0x14d0 0x162b 0x2b7d 0xa1a2 0x14c9 0x1622 0x2d77 0xa128 0x1493 0x15ea 0x2f71 0xa0b7 0x1479 0x15cd 0x316c 0xa04a 0x1464 0x15b6 0x3366 0x9fe5 0x1464 0x15b6 0x3560 0x9f7a 0x145e 0x15b0 0x375a 0x9efd 0x1442 0x1592 0x3954 0x9e83 0x1427 0x1575 0x3b4e 0x9e12 0x140d 0x155a 0x3d48 0x9da2 0x13fa 0x1547 0x3f42 0x9d29 0x13dd 0x1528 0x413c 0x9ca8 0x138f 0x14d4 0x4336 0x9c37 0x135a 0x149b 0x4530 0x9bc6 0x1337 0x1476 0x472a 0x9b55 0x1319 0x1457 0x4924 0x9ae5 0x12dd 0x1418 0x4b1e 0x9a79 0x12bf 0x13f7 0x4d18 0x9a15 0x129e 0x13d4 0x4f12 0x99b0 0x1284 0x13b8 0x510c 0x994c 0x126a 0x139b 0x5307 0x98e2 0x1244 0x1372 0x5501 0x987d 0x1230 0x135d 0x56fb 0x9825 0x1233 0x1360 0x58f5 0x97d3 0x1224 0x1353 0x5aef 0x9788 0x1231 0x135e 0x5ce9 0x973d 0x123f 0x136e 0x5ee3 0x96f8 0x124c 0x137b 0x60dd 0x96b3 0x124c 0x137b 0x62d7 0x966e 0x123f 0x136e 0x64d1 0x962f 0x125a 0x138b 0x66cb 0x95f7 0x1295 0x13c9 0x68c5 0x95bf 0x12b2 0x13e8 0x6abf 0x9587 0x12c0 0x13f8 0x6cb9 0x9554 0x12db 0x1415 0x6eb3 0x9529 0x1314 0x1451 0x70ad 0x94fd 0x1328 0x1465 0x72a8 0x94cb 0x133b 0x147b 0x74a2 0x94a0 0x1372 0x14b5 0x769c 0x9473 0x1387 0x14cc 0x7896 0x9450 0x13a8 0x14ee 0x7a90 0x9437 0x13e3 0x152c 0x7c8a 0x941e 0x141b 0x156b 0x7e84 0x9405 0x1452 0x15a3 0x807e 0x93ec 0x1487 0x15dc 0x8278 0x93db 0x14f8 0x1655 0x8472 0x93c6 0x155d 0x16c0 0x866c 0x93b6 0x15ec 0x1757 0x8866 0x93a1 0x16a7 0x1821 0x8a60 0x9387 0x1754 0x18d7 0x8c5a 0x936e 0x1821 0x19b2 0x8e54 0x9355 0x1962 0x1b07 0x904e 0x933c 0x1a2b 0x1bdd 0x9248 0x931a 0x1aef 0x1cae 0x9443 0x92f4 0x1bcc 0x1d9a 0x963d 0x92d8 0x1cc1 0x1e9f 0x9837 0x92b5 0x1dd0 0x1fbf 0x9a31 0x9290 0x1ee5 0x20e7 0x9c2b 0x9260 0x1fe5 0x21f8 0x9e25 0x922e 0x210c 0x2331 0xa01f 0x91f2 0x21fb 0x242f 0xa219 0x91be 0x2333 0x257b 0xa413 0x9181 0x2494 0x26f3 0xa60d 0x9142 0x262f 0x28aa 0xa807 0x90f9 0x27b5 0x2a49 0xaa01 0x90ae 0x29b2 0x2c66 0xabfb 0x906e 0x2c09 0x2ee4 0xadf5 0x9019 0x2e51 0x3152 0xafef 0x8fe3 0x3166 0x349a 0xb1e9 0x8fb1 0x3455 0x37ba 0xb3e4 0x8f8a 0x372b 0x3ac0 0xb5de 0x8f4d 0x39f8 0x3dbb 0xb7d8 0x8f0f 0x3db6 0x41b7 0xb9d2 0x8ead 0x4386 0x47e8 0xba3c 0x8de9 0x4fc9 0x54f6 0xbaa6 0x8de1 0x504a 0x557f 0xbb10 0x8de1 0x504a 0x557f 0xbb7a 0x8de1 0x504a 0x557f 0xbbe4 0x8de1 0x504a 0x557f>;
				battery3_profile_t0_num = <0x64>;
				battery3_profile_t0_col = <0x04>;
				battery3_profile_t0 = <0x00 0xacd9 0x375 0x2bc 0x204 0xac3d 0x375 0x2bc 0x408 0xabba 0x37c 0x2c1 0x60d 0xab3e 0x375 0x2bc 0x811 0xaace 0x373 0x2ba 0xa15 0xaa5b 0x373 0x2ba 0xc19 0xa9eb 0x36d 0x2b4 0xe1d 0xa97b 0x377 0x2bd 0x1021 0xa907 0x37c 0x2c1 0x1226 0xa893 0x37d 0x2c1 0x142a 0xa81b 0x37f 0x2c3 0x162e 0xa79f 0x378 0x2be 0x1832 0xa724 0x37f 0x2c3 0x1a36 0xa6a7 0x383 0x2c6 0x1c3b 0xa629 0x383 0x2c6 0x1e3f 0xa5a9 0x384 0x2c7 0x2043 0xa52c 0x387 0x2ca 0x2247 0xa4af 0x385 0x2c8 0x244b 0xa431 0x386 0x2c9 0x264f 0xa3b8 0x38f 0x2d0 0x2854 0xa33e 0x393 0x2d3 0x2a58 0xa2c5 0x398 0x2d7 0x2c5c 0xa24a 0x395 0x2d4 0x2e60 0xa1cf 0x391 0x2d1 0x3064 0xa15b 0x398 0x2d7 0x3269 0xa0e5 0x3a1 0x2de 0x346d 0xa074 0x3a2 0x2df 0x3671 0xa001 0x3a9 0x2e4 0x3875 0x9f8e 0x3a9 0x2e4 0x3a79 0x9f21 0x3aa 0x2e5 0x3c7d 0x9eb0 0x3a9 0x2e4 0x3e82 0x9e4a 0x3b1 0x314 0x4086 0x9de1 0x3b9 0x31b 0x428a 0x9d7b 0x3c3 0x323 0x448e 0x9d18 0x3cb 0x32a 0x4692 0x9cb8 0x3d3 0x330 0x4897 0x9c58 0x3e2 0x33d 0x4a9b 0x9bf8 0x3e9 0x343 0x4c9f 0x9b9d 0x3f5 0x34d 0x4ea3 0x9b45 0x40a 0x35e 0x50a7 0x9ae9 0x41c 0x36d 0x52ab 0x9a8c 0x433 0x380 0x54b0 0x9a1f 0x432 0x37f 0x56b4 0x998f 0x3f8 0x34f 0x58b8 0x98f3 0x3a7 0x30c 0x5abc 0x987b 0x38a 0x2f4 0x5cc0 0x9821 0x387 0x2f1 0x5ec5 0x97d3 0x384 0x2ef 0x60c9 0x978b 0x37e 0x2e9 0x62cd 0x9746 0x37a 0x2e7 0x64d1 0x9708 0x37f 0x2ea 0x66d5 0x96cd 0x37e 0x2e9 0x68d9 0x9693 0x382 0x2ed 0x6ade 0x9659 0x37f 0x2ea 0x6ce2 0x9624 0x380 0x2eb 0x6ee6 0x95f3 0x389 0x2f3 0x70ea 0x95c0 0x389 0x2f3 0x72ee 0x9593 0x391 0x2f9 0x74f3 0x9565 0x391 0x2f9 0x76f7 0x9539 0x393 0x2fb 0x78fb 0x950f 0x39a 0x301 0x7aff 0x94e5 0x398 0x2ff 0x7d03 0x94c2 0x3a9 0x30e 0x7f07 0x949c 0x3a3 0x308 0x810c 0x947c 0x3b2 0x315 0x8310 0x9459 0x3c1 0x321 0x8514 0x9439 0x3c9 0x329 0x8718 0x9419 0x3d1 0x32e 0x891c 0x93f7 0x3d1 0x32e 0x8b21 0x93c6 0x3c7 0x327 0x8d25 0x9376 0x398 0x2ff 0x8f29 0x9324 0x37c 0x2e7 0x912d 0x92e2 0x380 0x2eb 0x9331 0x92b2 0x38b 0x2f4 0x9535 0x9284 0x38d 0x2f6 0x973a 0x9257 0x38c 0x2f5 0x993e 0x9225 0x386 0x2f0 0x9b42 0x91fa 0x38f 0x2f7 0x9d46 0x91d3 0x392 0x2fa 0x9f4a 0x91ac 0x39a 0x301 0xa14f 0x917d 0x39e 0x304 0xa353 0x913f 0x394 0x2fc 0xa557 0x90fc 0x38c 0x2f5 0xa75b 0x90bd 0x393 0x2fb 0xa95f 0x9079 0x39a 0x301 0xab63 0x9025 0x382 0x2ed 0xad68 0x8fe9 0x368 0x2d7 0xaf6c 0x8fd1 0x370 0x2de 0xb170 0x8fc9 0x38e 0x2f7 0xb374 0x8fbd 0x3ad 0x310 0xb578 0x8fad 0x3d3 0x330 0xb77d 0x8f92 0x40a 0x35e 0xb981 0x8f32 0x40d 0x37c 0xbb85 0x8ded 0x3b9 0x334 0xbbd8 0x8bf6 0x3d1 0x348 0xbc2b 0x8948 0x402 0x372 0xbc7e 0x882a 0x44c 0x3b2 0xbcd1 0x870c 0x508 0x454 0xbd24 0x85ee 0x508 0x454 0xbd74 0x84d0 0x508 0x454>;
				battery3_profile_t1_num = <0x64>;
				battery3_profile_t1_col = <0x04>;
				battery3_profile_t1 = <0x00 0xad5b 0x454 0x36c 0x204 0xaca3 0x453 0x36b 0x408 0xac18 0x44e 0x367 0x60d 0xab9c 0x445 0x360 0x811 0xab29 0x443 0x35e 0xa15 0xaaba 0x437 0x354 0xc19 0xaa4d 0x43c 0x359 0xe1d 0xa9e1 0x439 0x356 0x1021 0xa972 0x446 0x360 0x1226 0xa8ff 0x44c 0x365 0x142a 0xa886 0x447 0x361 0x162e 0xa80c 0x442 0x35d 0x1832 0xa793 0x44d 0x366 0x1a36 0xa717 0x44b 0x364 0x1c3b 0xa699 0x446 0x360 0x1e3f 0xa61c 0x44e 0x367 0x2043 0xa5a0 0x456 0x36d 0x2247 0xa520 0x451 0x36a 0x244b 0xa4a4 0x454 0x36c 0x264f 0xa428 0x45f 0x374 0x2854 0xa3ac 0x462 0x377 0x2a58 0xa32f 0x459 0x36f 0x2c5c 0xa2b7 0x45f 0x374 0x2e60 0xa23f 0x46f 0x381 0x3064 0xa1c7 0x479 0x389 0x3269 0xa153 0x47f 0x38d 0x346d 0xa0de 0x482 0x390 0x3671 0xa06a 0x48f 0x39a 0x3875 0x9ff8 0x48e 0x399 0x3a79 0x9f8a 0x49f 0x3a7 0x3c7d 0x9f1e 0x4aa 0x3b0 0x3e82 0x9eb3 0x4b0 0x3e9 0x4086 0x9e47 0x4ba 0x3f2 0x428a 0x9dde 0x4c9 0x3fe 0x448e 0x9d7b 0x4e3 0x413 0x4692 0x9d17 0x4f8 0x425 0x4897 0x9cb7 0x515 0x43d 0x4a9b 0x9c55 0x51e 0x446 0x4c9f 0x9bf6 0x522 0x448 0x4ea3 0x9b9d 0x53b 0x45d 0x50a7 0x9b44 0x554 0x472 0x52ab 0x9ae8 0x56b 0x486 0x54b0 0x9a84 0x569 0x484 0x56b4 0x9a16 0x554 0x472 0x58b8 0x9992 0x512 0x43a 0x5abc 0x9907 0x4b6 0x3ee 0x5cc0 0x9888 0x469 0x3ae 0x5ec5 0x9821 0x43e 0x38a 0x60c9 0x97c9 0x429 0x379 0x62cd 0x977f 0x41f 0x36f 0x64d1 0x973a 0x41b 0x36d 0x66d5 0x96fa 0x41b 0x36d 0x68d9 0x96be 0x420 0x370 0x6ade 0x9686 0x425 0x375 0x6ce2 0x964d 0x41a 0x36d 0x6ee6 0x961a 0x41c 0x36d 0x70ea 0x95ea 0x422 0x372 0x72ee 0x95bd 0x431 0x37e 0x74f3 0x9589 0x423 0x373 0x76f7 0x955c 0x417 0x36a 0x78fb 0x9536 0x409 0x35d 0x7aff 0x9510 0x40e 0x361 0x7d03 0x94e6 0x407 0x35c 0x7f07 0x94c5 0x414 0x367 0x810c 0x94a2 0x415 0x368 0x8310 0x9485 0x424 0x374 0x8514 0x9465 0x424 0x374 0x8718 0x9445 0x424 0x374 0x891c 0x9428 0x42c 0x37c 0x8b21 0x940d 0x436 0x383 0x8d25 0x93f1 0x432 0x37f 0x8f29 0x93c8 0x418 0x36b 0x912d 0x93a7 0x427 0x377 0x9331 0x937d 0x40d 0x360 0x9535 0x9352 0x3f2 0x34b 0x973a 0x9329 0x3f1 0x34a 0x993e 0x92fb 0x3db 0x338 0x9b42 0x92d0 0x3db 0x338 0x9d46 0x92a6 0x3d3 0x330 0x9f4a 0x9281 0x3dc 0x338 0xa14f 0x925e 0x3e1 0x33c 0xa353 0x9236 0x3df 0x33a 0xa557 0x9205 0x3e6 0x340 0xa75b 0x91c5 0x3e6 0x340 0xa95f 0x9180 0x3de 0x33a 0xab63 0x9144 0x3e4 0x33e 0xad68 0x9101 0x3ed 0x346 0xaf6c 0x90ac 0x3e4 0x33e 0xb170 0x906e 0x3db 0x338 0xb374 0x9058 0x3e3 0x33e 0xb578 0x9048 0x3ed 0x346 0xb77d 0x903b 0x402 0x358 0xb981 0x902b 0x426 0x392 0xbb85 0x900f 0x453 0x3b9 0xbbd8 0x8fb5 0x47d 0x3dc 0xbc2b 0x8e80 0x459 0x3be 0xbc7e 0x8c7d 0x45a 0x3d2 0xbcd1 0x89ee 0x49d 0x40d 0xbd24 0x875f 0x529 0x488 0xbd74 0x84d0 0x744 0x662>;
				battery3_profile_t2_num = <0x64>;
				battery3_profile_t2_col = <0x04>;
				battery3_profile_t2 = <0x00 0xacbd 0x846 0x846 0x204 0xac18 0x846 0x846 0x408 0xab9f 0x844 0x844 0x60d 0xab2d 0x833 0x833 0x811 0xaac3 0x823 0x823 0xa15 0xaa57 0x815 0x815 0xc19 0xa9ef 0x818 0x818 0xe1d 0xa97d 0x7fd 0x7fd 0x1021 0xa90b 0x7f0 0x7f0 0x1226 0xa896 0x7df 0x7df 0x142a 0xa820 0x7d8 0x7d8 0x162e 0xa7a5 0x7c9 0x7c9 0x1832 0xa72a 0x7c2 0x7c2 0x1a36 0xa6ac 0x7b4 0x7b4 0x1c3b 0xa62c 0x7a9 0x7a9 0x1e3f 0xa5ae 0x7a1 0x7a1 0x2043 0xa531 0x7a1 0x7a1 0x2247 0xa4b5 0x79d 0x79d 0x244b 0xa438 0x795 0x795 0x264f 0xa3be 0x792 0x792 0x2854 0xa344 0x796 0x796 0x2a58 0xa2c9 0x78f 0x78f 0x2c5c 0xa252 0x794 0x794 0x2e60 0xa1db 0x7a0 0x7a0 0x3064 0xa167 0x7a1 0x7a1 0x3269 0xa0f1 0x795 0x795 0x346d 0xa080 0x7a5 0x7a5 0x3671 0xa00a 0x7a2 0x7a2 0x3875 0x9f9c 0x7af 0x7af 0x3a79 0x9f2f 0x7b6 0x7b6 0x3c7d 0x9ec5 0x7ce 0x7ce 0x3e82 0x9e55 0x7d7 0x7d7 0x4086 0x9de9 0x7ee 0x7ee 0x428a 0x9d7d 0x800 0x800 0x448e 0x9d13 0x805 0x805 0x4692 0x9cad 0x810 0x810 0x4897 0x9c4a 0x81e 0x81e 0x4a9b 0x9bea 0x81e 0x81e 0x4c9f 0x9b86 0x81c 0x81c 0x4ea3 0x9b1e 0x811 0x811 0x50a7 0x9aae 0x7f6 0x7f6 0x52ab 0x9a3d 0x7cf 0x7cf 0x54b0 0x99c2 0x78f 0x78f 0x56b4 0x9946 0x74d 0x74d 0x58b8 0x98d1 0x70a 0x70a 0x5abc 0x9869 0x6d9 0x6d9 0x5cc0 0x9809 0x6b5 0x6b5 0x5ec5 0x97b4 0x69a 0x69a 0x60c9 0x9767 0x68e 0x68e 0x62cd 0x9720 0x687 0x687 0x64d1 0x96df 0x684 0x684 0x66d5 0x96a1 0x684 0x684 0x68d9 0x9668 0x682 0x682 0x6ade 0x962f 0x67c 0x67c 0x6ce2 0x95fe 0x68f 0x68f 0x6ee6 0x95c9 0x689 0x689 0x70ea 0x9598 0x693 0x693 0x72ee 0x956b 0x693 0x693 0x74f3 0x9541 0x698 0x698 0x76f7 0x9515 0x6a0 0x6a0 0x78fb 0x94eb 0x6a8 0x6a8 0x7aff 0x94c7 0x6af 0x6af 0x7d03 0x94a1 0x6b1 0x6b1 0x7f07 0x9480 0x6b1 0x6b1 0x810c 0x9460 0x6b8 0x6b8 0x8310 0x9443 0x6c7 0x6c7 0x8514 0x9424 0x6bf 0x6bf 0x8718 0x940a 0x6c0 0x6c0 0x891c 0x93ee 0x6c2 0x6c2 0x8b21 0x93d4 0x6c1 0x6c1 0x8d25 0x93ba 0x6b8 0x6b8 0x8f29 0x93a1 0x6b9 0x6b9 0x912d 0x938b 0x6c2 0x6c2 0x9331 0x9374 0x6cf 0x6cf 0x9535 0x9358 0x6da 0x6da 0x973a 0x9333 0x6c7 0x6c7 0x993e 0x9307 0x6bf 0x6bf 0x9b42 0x92d8 0x6bc 0x6bc 0x9d46 0x92ac 0x6cd 0x6cd 0x9f4a 0x9283 0x6e8 0x6e8 0xa14f 0x9255 0x704 0x704 0xa353 0x921b 0x720 0x720 0xa557 0x91db 0x740 0x740 0xa75b 0x919a 0x757 0x757 0xa95f 0x915a 0x770 0x770 0xab63 0x9111 0x79a 0x79a 0xad68 0x90b6 0x7b4 0x7b4 0xaf6c 0x9075 0x7ce 0x7ce 0xb170 0x9054 0x7fd 0x7fd 0xb374 0x903d 0x842 0x842 0xb578 0x9025 0x8a1 0x8a1 0xb77d 0x900b 0x934 0x934 0xb981 0x8fda 0x9ed 0x9ed 0xbb85 0x8f6f 0xaf7 0xaf7 0xbbd8 0x8e35 0xc1d 0xc1d 0xbc2b 0x8c1f 0xe60 0xe60 0xbc7e 0x8940 0x13a2 0x13a2 0xbcd1 0x8509 0x2218 0x2218 0xbd24 0x84f5 0x225e 0x225e 0xbd74 0x84f5 0x225e 0x225e>;
				battery3_profile_t3_num = <0x64>;
				battery3_profile_t3_col = <0x04>;
				battery3_profile_t3 = <0x00 0xad5e 0xc15 0xc15 0x204 0xac83 0xc15 0xc15 0x408 0xabeb 0xc22 0xc22 0x60d 0xab6f 0xc0c 0xc0c 0x811 0xaafd 0xbfc 0xbfc 0xa15 0xaa90 0xbed 0xbed 0xc19 0xaa21 0xbec 0xbec 0xe1d 0xa9b5 0xbd9 0xbd9 0x1021 0xa943 0xbc5 0xbc5 0x1226 0xa8d3 0xbb9 0xbb9 0x142a 0xa85d 0xba1 0xba1 0x162e 0xa7e2 0xb8d 0xb8d 0x1832 0xa768 0xb86 0xb86 0x1a36 0xa6ea 0xb7b 0xb7b 0x1c3b 0xa66f 0xb71 0xb71 0x1e3f 0xa5f4 0xb66 0xb66 0x2043 0xa576 0xb50 0xb50 0x2247 0xa4fa 0xb49 0xb49 0x244b 0xa47d 0xb3f 0xb3f 0x264f 0xa401 0xb38 0xb38 0x2854 0xa385 0xb32 0xb32 0x2a58 0xa30c 0xb31 0xb31 0x2c5c 0xa294 0xb34 0xb34 0x2e60 0xa21b 0xb2e 0xb2e 0x3064 0xa1a4 0xb32 0xb32 0x3269 0xa12e 0xb34 0xb34 0x346d 0xa0ba 0xb41 0xb41 0x3671 0xa047 0xb3d 0xb3d 0x3875 0x9fd7 0xb3d 0xb3d 0x3a79 0x9f66 0xb58 0xb58 0x3c7d 0x9efa 0xb77 0xb77 0x3e82 0x9e87 0xb8f 0xb8f 0x4086 0x9e13 0xb97 0xb97 0x428a 0x9da1 0xb90 0xb90 0x448e 0x9d31 0xb8f 0xb8f 0x4692 0x9cc1 0xb7f 0xb7f 0x4897 0x9c52 0xb6a 0xb6a 0x4a9b 0x9be8 0xb5d 0xb5d 0x4c9f 0x9b78 0xb36 0xb36 0x4ea3 0x9b08 0xb13 0xb13 0x50a7 0x9a94 0xae5 0xae5 0x52ab 0x9a21 0xaba 0xaba 0x54b0 0x99ab 0xa81 0xa81 0x56b4 0x993a 0xa4e 0xa4e 0x58b8 0x98d0 0xa2a 0xa2a 0x5abc 0x986d 0xa0d 0xa0d 0x5cc0 0x9812 0x9f4 0x9f4 0x5ec5 0x97bd 0x9e4 0x9e4 0x60c9 0x9770 0x9db 0x9db 0x62cd 0x9726 0x9d2 0x9d2 0x64d1 0x96e0 0x9d7 0x9d7 0x66d5 0x969f 0x9db 0x9db 0x68d9 0x9663 0x9e1 0x9e1 0x6ade 0x9629 0x9ec 0x9ec 0x6ce2 0x95f2 0x9fa 0x9fa 0x6ee6 0x95bc 0x9fe 0x9fe 0x70ea 0x958b 0xa0e 0xa0e 0x72ee 0x955c 0xa1c 0xa1c 0x74f3 0x952f 0xa2a 0xa2a 0x76f7 0x9505 0xa39 0xa39 0x78fb 0x94d9 0xa3c 0xa3c 0x7aff 0x94b2 0xa49 0xa49 0x7d03 0x948b 0xa59 0xa59 0x7f07 0x946a 0xa68 0xa68 0x810c 0x9447 0xa77 0xa77 0x8310 0x9427 0xa78 0xa78 0x8514 0x940a 0xa87 0xa87 0x8718 0x93ef 0xa84 0xa84 0x891c 0x93db 0xaa3 0xaa3 0x8b21 0x93c8 0xac2 0xac2 0x8d25 0x93b5 0xae6 0xae6 0x8f29 0x93a1 0xb1d 0xb1d 0x912d 0x938b 0xb4f 0xb4f 0x9331 0x9374 0xb90 0xb90 0x9535 0x935a 0xbd4 0xbd4 0x973a 0x933b 0xc26 0xc26 0x993e 0x9316 0xc7b 0xc7b 0x9b42 0x92ed 0xcd3 0xcd3 0x9d46 0x92c4 0xd3e 0xd3e 0x9f4a 0x9295 0xdae 0xdae 0xa14f 0x9261 0xe22 0xe22 0xa353 0x9225 0xe9b 0xe9b 0xa557 0x91e1 0xf19 0xf19 0xa75b 0x919c 0xfad 0xfad 0xa95f 0x9156 0x104e 0x104e 0xab63 0x9106 0x10f7 0x10f7 0xad68 0x90ae 0x11b2 0x11b2 0xaf6c 0x9063 0x1286 0x1286 0xb170 0x902b 0x138c 0x138c 0xb374 0x9005 0x14e2 0x14e2 0xb578 0x8fe3 0x1683 0x1683 0xb77d 0x8fba 0x18b5 0x18b5 0xb981 0x8f7e 0x1ba1 0x1ba1 0xbb85 0x8f14 0x1fbe 0x1fbe 0xbbd8 0x8e1b 0x25e4 0x25e4 0xbc2b 0x8c49 0x310f 0x310f 0xbc7e 0x89b7 0x4852 0x4852 0xbcd1 0x899b 0x4955 0x4955 0xbd24 0x899b 0x4955 0x4955 0xbd74 0x899b 0x4955 0x4955>;
				battery3_profile_t4_num = <0x64>;
				battery3_profile_t4_col = <0x04>;
				battery3_profile_t4 = <0x00 0xacbd 0x1ae3 0x1ae3 0x204 0xabc0 0x1ae4 0x1ae4 0x408 0xab1b 0x1b1b 0x1b1b 0x60d 0xaa83 0x1abf 0x1abf 0x811 0xa9f6 0x1a84 0x1a84 0xa15 0xa96b 0x1a78 0x1a78 0xc19 0xa8ee 0x1a24 0x1a24 0xe1d 0xa87a 0x1a0a 0x1a0a 0x1021 0xa802 0x19ed 0x19ed 0x1226 0xa77c 0x1985 0x1985 0x142a 0xa705 0x195e 0x195e 0x162e 0xa68a 0x1927 0x1927 0x1832 0xa616 0x18fb 0x18fb 0x1a36 0xa59e 0x18ba 0x18ba 0x1c3b 0xa51e 0x187a 0x187a 0x1e3f 0xa4a5 0x1857 0x1857 0x2043 0xa432 0x1849 0x1849 0x2247 0xa3b8 0x1808 0x1808 0x244b 0xa33f 0x17cb 0x17cb 0x264f 0xa2cd 0x17ab 0x17ab 0x2854 0xa259 0x1789 0x1789 0x2a58 0xa1e6 0x177e 0x177e 0x2c5c 0xa16b 0x1755 0x1755 0x2e60 0xa0f4 0x172a 0x172a 0x3064 0xa081 0x170c 0x170c 0x3269 0xa017 0x1703 0x1703 0x346d 0x9fb1 0x1702 0x1702 0x3671 0x9f37 0x16e9 0x16e9 0x3875 0x9eb7 0x16c8 0x16c8 0x3a79 0x9e42 0x16a7 0x16a7 0x3c7d 0x9dcf 0x168a 0x168a 0x3e82 0x9d5c 0x1685 0x1685 0x4086 0x9cd1 0x162b 0x162b 0x428a 0x9c5d 0x15ea 0x15ea 0x448e 0x9beb 0x15ae 0x15ae 0x4692 0x9b77 0x15a8 0x15a8 0x4897 0x9b04 0x154c 0x154c 0x4a9b 0x9a93 0x152d 0x152d 0x4c9f 0x9a2d 0x150e 0x150e 0x4ea3 0x99c6 0x14ed 0x14ed 0x50a7 0x9960 0x14ce 0x14ce 0x52ab 0x98f7 0x14a7 0x14a7 0x54b0 0x988b 0x147f 0x147f 0x56b4 0x9832 0x148f 0x148f 0x58b8 0x97dc 0x1477 0x1477 0x5abc 0x978f 0x1481 0x1481 0x5cc0 0x9743 0x1497 0x1497 0x5ec5 0x96fc 0x14a5 0x14a5 0x60c9 0x96b6 0x14a8 0x14a8 0x62cd 0x966f 0x1496 0x1496 0x64d1 0x962f 0x14b6 0x14b6 0x66d5 0x95f6 0x14f7 0x14f7 0x68d9 0x95bc 0x1513 0x1513 0x6ade 0x9584 0x1525 0x1525 0x6ce2 0x9550 0x1544 0x1544 0x6ee6 0x9525 0x158e 0x158e 0x70ea 0x94f7 0x1599 0x1599 0x72ee 0x94c4 0x15bc 0x15bc 0x74f3 0x949a 0x15fb 0x15fb 0x76f7 0x946a 0x160b 0x160b 0x78fb 0x944b 0x163c 0x163c 0x7aff 0x9432 0x167e 0x167e 0x7d03 0x9418 0x16be 0x16be 0x7f07 0x93fe 0x16fd 0x16fd 0x810c 0x93e5 0x173d 0x173d 0x8310 0x93d7 0x17d7 0x17d7 0x8514 0x93be 0x1838 0x1838 0x8718 0x93b1 0x18fa 0x18fa 0x891c 0x9397 0x19d8 0x19d8 0x8b21 0x937e 0x1a9d 0x1a9d 0x8d25 0x9364 0x1bae 0x1bae 0x8f29 0x934a 0x1d28 0x1d28 0x912d 0x932f 0x1dda 0x1dda 0x9331 0x9308 0x1ed7 0x1ed7 0x9535 0x92e5 0x1fde 0x1fde 0x973a 0x92c8 0x2107 0x2107 0x993e 0x92a2 0x2246 0x2246 0x9b42 0x9277 0x237b 0x237b 0x9d46 0x9244 0x24b3 0x24b3 0x9f4a 0x920d 0x25ee 0x25ee 0xa14f 0x91d2 0x2721 0x2721 0xa353 0x9199 0x28ad 0x28ad 0xa557 0x9159 0x2a6a 0x2a6a 0xa75b 0x9113 0x2c3a 0x2c3a 0xa95f 0x90c6 0x2e4d 0x2e4d 0xab63 0x9080 0x30e1 0x30e1 0xad68 0x9031 0x338c 0x338c 0xaf6c 0x8ff0 0x36cb 0x36cb 0xb170 0x8fbd 0x3a40 0x3a40 0xb374 0x8f92 0x3d89 0x3d89 0xb578 0x8f5a 0x40c7 0x40c7 0xb77d 0x8f1a 0x44d8 0x44d8 0xb981 0x8ebd 0x4b1f 0x4b1f 0xbb85 0x8e05 0x5806 0x5806 0xbbd8 0x8de1 0x5a94 0x5a94 0xbc2b 0x8de1 0x5a94 0x5a94 0xbc7e 0x8de1 0x5a94 0x5a94 0xbcd1 0x8de1 0x5a94 0x5a94 0xbd24 0x8de1 0x5a94 0x5a94 0xbd74 0x8de1 0x5a94 0x5a94>;
				g_PMIC_MIN_VOL_row = <0x04>;
				g_PMIC_MIN_VOL_col = <0x0a>;
				g_PMIC_MIN_VOL = <0x8854 0x82dc 0x8660 0x8854 0x8854 0x80e8 0x8660 0x8854 0x80e8 0x80e8 0x8660 0x84d0 0x7dc8 0x7dc8 0x8660 0x8408 0x7918 0x7918 0x8660 0x7918 0x7b0c 0x7b0c 0x7b0c 0x7b0c 0x7918 0x7918 0x7918 0x7918 0x7918 0x7918 0x7918 0x7918 0x7918 0x7918 0x7918 0x7918 0x7918 0x7918 0x7918 0x79e0>;
				g_PON_SYS_IBOOT_row = <0x04>;
				g_PON_SYS_IBOOT_col = <0x0a>;
				g_PON_SYS_IBOOT = <0x1388 0x1388 0x1388 0x1388 0x1388 0x1388 0x1388 0x1388 0x1388 0x1388 0x1388 0x1388 0x1388 0x1388 0x1388 0x1388 0x1388 0x1388 0x1388 0x1388 0x1388 0x1388 0x1388 0x1388 0x1388 0x1388 0x1388 0x1388 0x1388 0x1388 0x1388 0x1388 0x1388 0x1388 0x1388 0x1388 0x1388 0x1388 0x1388 0x1388>;
				g_QMAX_SYS_VOL_row = <0x04>;
				g_QMAX_SYS_VOL_col = <0x0a>;
				g_QMAX_SYS_VOL = <0x8886 0x8886 0x8886 0x86c4 0x8886 0x8886 0x8886 0x86c4 0x85ca 0x85ca 0x85ca 0x85ca 0x85ca 0x85ca 0x85ca 0x85ca 0x85ca 0x85ca 0x85ca 0x85ca 0x7ef4 0x7ef4 0x7ef4 0x7ef4 0x8020 0x8020 0x8020 0x8020 0x8020 0x8020 0x8020 0x8020 0x8020 0x8020 0x8020 0x8020 0x8020 0x8020 0x8020 0x8020>;
				g_FG_PSEUDO100_row = <0x04>;
				g_FG_PSEUDO100_col = <0x0a>;
				g_FG_PSEUDO100 = <0x61 0x61 0x61 0x61 0x61 0x61 0x61 0x61 0x61 0x61 0x61 0x61 0x61 0x61 0x61 0x61 0x61 0x61 0x61 0x61 0x64 0x64 0x64 0x64 0x64 0x64 0x64 0x64 0x64 0x64 0x64 0x64 0x64 0x64 0x64 0x64 0x64 0x64 0x64 0x64>;
				g_FG_charge_PSEUDO100_row = <0x04>;
				g_FG_charge_PSEUDO100_col = <0x0a>;
				g_FG_charge_PSEUDO100 = <0x64 0x64 0x64 0x64 0x64 0x64 0x64 0x64 0x64 0x64 0x64 0x64 0x64 0x64 0x64 0x64 0x64 0x64 0x64 0x64 0x64 0x64 0x64 0x64 0x64 0x64 0x64 0x64 0x64 0x64 0x64 0x64 0x64 0x64 0x64 0x64 0x64 0x64 0x64 0x64>;
			};

			mtk_chrdet: mtk_chrdet {
				compatible = "mediatek,mtk-chr-det";
				io-channels = <&pmic_auxadc 2>;
				io-channel-names = "pmic_vbus";
				bootmode = <&chosen>;
				bc12 = <&mt6375_chg>;
				vcdt_int_active;
			};

			mt6358_batoc_throttle: mtk_battery_oc_throttling {
				compatible = "mediatek,mt6358-battery_oc_throttling";
				oc-thd = <0x1770 0x1b58 0x1f40>;
			};
		};
	};

	pwraph: pwraphal@10026000 {
		compatible = "mediatek,pwraph";
		mediatek,pwrap-regmap = <&pwrap>;
	};

	pwrap_mpu@10026000 {
		compatible = "mediatek,pwrap_mpu";
		reg = <0x00 0x10026000 0x00 0x1000>;
	};

	vow_pmic_efuse {
		compatible = "mediatek,vow-efuse";
		nvmem = <&pmic_efuse>;
		nvmem-names = "vow_efuse_device";
		ver_reg = <0xec>;
		ver_mask = <0x1f>;
	};

};
